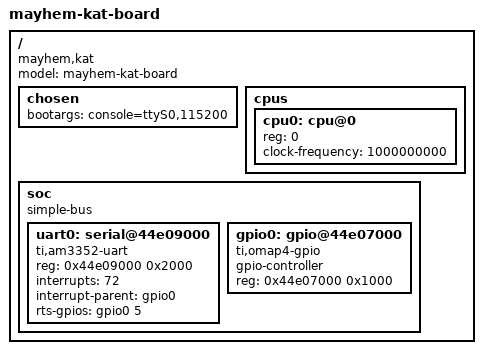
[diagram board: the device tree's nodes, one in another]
/dts-v1/;

/ {
	model = "mayhem-kat-board";
	compatible = "mayhem,kat", "ti,am335x";
	#address-cells = <1>;
	#size-cells = <1>;

	chosen {
		bootargs = "console=ttyS0,115200";
	};

	cpus {
		#address-cells = <1>;
		#size-cells = <0>;
		cpu0: cpu@0 {
			device_type = "cpu";
			reg = <0>;
			clock-frequency = <1000000000>;
		};
	};

	soc {
		compatible = "simple-bus";
		#address-cells = <1>;
		#size-cells = <1>;
		ranges;
		uart0: serial@44e09000 {
			compatible = "ti,am3352-uart";
			reg = <0x44e09000 0x2000>;
			interrupts = <72>;
			interrupt-parent = <&gpio0>;
			rts-gpios = <&gpio0 5 0>;
			status = "okay";
		};
		gpio0: gpio@44e07000 {
			compatible = "ti,omap4-gpio";
			gpio-controller;
			#gpio-cells = <2>;
			reg = <0x44e07000 0x1000>;
		};
	};
};
